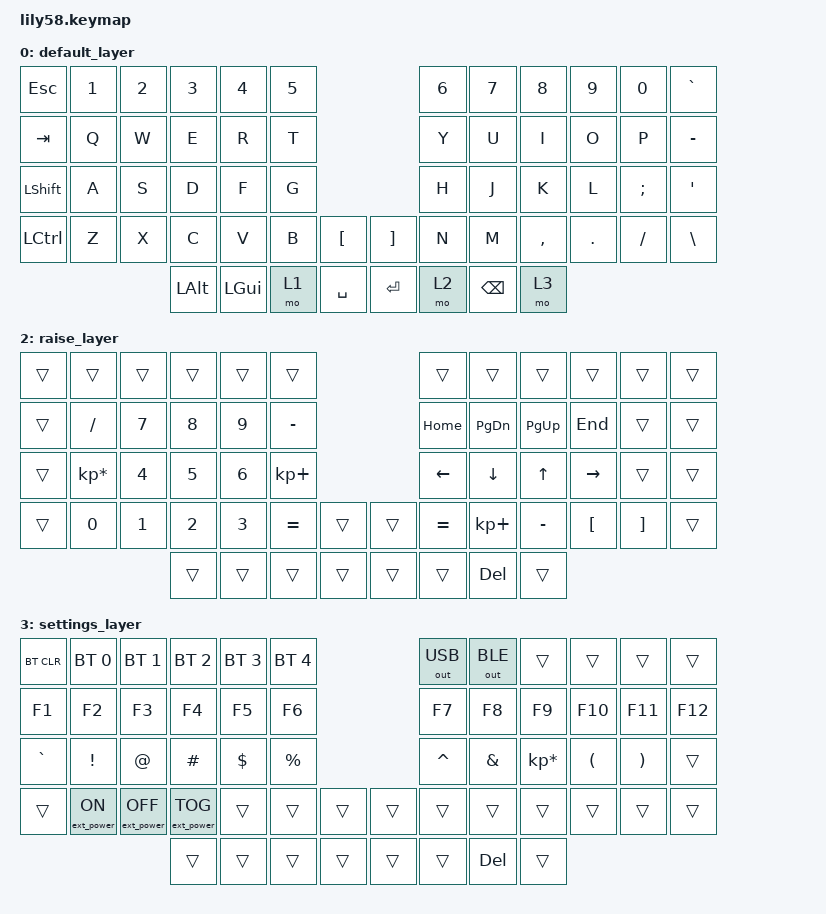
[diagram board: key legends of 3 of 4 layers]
/*
 * Copyright (c) 2020 The ZMK Contributors
 *
 * SPDX-License-Identifier: MIT
 */

#include <behaviors.dtsi>
#include <dt-bindings/zmk/keys.h>
#include <dt-bindings/zmk/bt.h>
#include <dt-bindings/zmk/ext_power.h>
#include <dt-bindings/zmk/outputs.h>

/ {
	keymap {
		compatible = "zmk,keymap";

		default_layer {
// ------------------------------------------------------------------------------------------------------------
// |  ESC  |  1  |  2  |  3   |  4   |  5   |                   |  6   |  7    |  8    |  9   |   0   |   `   |
// |  TAB  |  Q  |  W  |  E   |  R   |  T   |                   |  Y   |  U    |  I    |  O   |   P   |   -   |
// | SHIFT |  A  |  S  |  D   |  F   |  G   |                   |  H   |  J    |  K    |  L   |   ;   |   '   |
// | CTRL  |  Z  |  X  |  C   |  V   |  B   |   "["  |  |  "]"  |  N   |  M    |  ,    |  .   |   /   |   \   |
//                     | ALT  | GUI  | LOWER|  SPACE |  | ENTER | RAISE| BSPC  |SETTINGS|
			bindings = <
&kp ESC   &kp N1 &kp N2 &kp N3   &kp N4   &kp N5                     &kp N6 &kp N7   &kp N8    &kp N9  &kp N0   &kp GRAVE
&kp TAB   &kp Q  &kp W  &kp E    &kp R    &kp T                      &kp Y  &kp U    &kp I     &kp O   &kp P    &kp MINUS
&kp LSHFT &kp A  &kp S  &kp D    &kp F    &kp G                      &kp H  &kp J    &kp K     &kp L   &kp SEMI &kp SQT
&kp LCTRL &kp Z  &kp X  &kp C    &kp V    &kp B  &kp LBKT   &kp RBKT &kp N  &kp M    &kp COMMA &kp DOT &kp FSLH &kp BACKSLASH
                        &kp LALT &kp LGUI &mo 1  &kp SPACE  &kp RET  &mo 2  &kp BSPC &mo 3
			>;

			sensor-bindings = <&inc_dec_kp C_VOL_UP C_VOL_DN>;
		};

		lower_layer {
// ------------------------------------------------------------------------------------------------------------
// |       |  F1 |  F2 |  F3  |  F4  |  F5  |                   |  F6  |  F7   |  F8   |  F9  |  F10  |  F11  |
// |   `   |  !  |  @  |  #   |  $   |  %   |                   |  ^   |  &    |  *    |  (   |   )   |  F12  |
// | SHIFT |  1  |  2  |  3   |  4   |  5   |                   |  6   |   7   |   8   |  9   |   0   |       |
// |       |     |     |      |      |      |        |  |       |  =   |  +    |  -    |  {   |   }   |       |
//                     |      |      |      |        |  |       |      |  DEL  |       |
			bindings = <
&trans 		&kp F1      &kp F2	&kp F3		&kp F4		&kp F5                 	&kp F6		&kp F7    	&kp F8    		&kp F9		&kp F10   &kp F11
&kp GRAVE   &kp EXCL    &kp AT	&kp HASH	&kp DOLLAR	&kp PRCNT              	&kp CARET	&kp AMPS  	&kp KP_MULTIPLY	&kp LPAR 	&kp RPAR  &kp F12
&kp LSHFT 	&kp N1 	    &kp N2 	&kp N3  	&kp N4  	&kp N5                 	&kp N6     	&kp N7    	&kp N8    		&kp N9   	&kp N0    &trans
&trans     	&trans	    &trans 	&trans 		&trans      &trans   				&kp EQUAL   &kp KP_PLUS &kp MINUS		&kp LBRC  &kp RBRC    &trans
                                              &trans            &trans       &trans    &trans   &trans    &mo 3    &kp DEL    &trans
			>;

			sensor-bindings = <&inc_dec_kp C_VOL_UP C_VOL_DN>;
		};

		raise_layer {
// ------------------------------------------------------------------------------------------------------------
// |       |     |     |      |      |      |                   |      |       |       |      |       |       |
// |       |  /  |  7  |  8   |  9   |  -   |                   | HOME | PGDN  | PGUP  | END  |       |       |
// |       |  *  |  4  |  5   |  6   |  +   |                   |  <-  |   v   |   ^   |  ->  |       |       |
// |       |  0  |  1  |  2   |  3   |  =   |        |  |       |  =   |   +   |   -   |  [   |   ]   |       |
//                     |      |  .   |      |        |  |       |      |  DEL  |       |
			bindings = <
&trans    &trans &trans &trans  &trans  &trans                       &trans      &trans    &trans    &trans    &trans    &trans
&trans    &kp FSLH &kp N7 &kp N8  &kp N9  &kp MINUS                       &kp HOME      &kp PG_DN    &kp PG_UP    &kp END    &trans    &trans
&trans    &kp KP_MULTIPLY &kp N4 &kp N5  &kp N6  &kp KP_PLUS                       &kp LEFT    &kp DOWN  &kp UP    &kp RIGHT &trans &trans
&trans    &kp N0 &kp N1 &kp N2 &kp N3 &kp EQUAL   &trans   &trans    &kp EQUAL &kp KP_PLUS &kp MINUS &kp LBKT  &kp RBKT  &trans
                        &trans  &trans  &trans    &trans   &trans    &trans      &kp DEL    &trans
			>;

			sensor-bindings = <&inc_dec_kp C_VOL_UP C_VOL_DN>;
		};

		settings_layer {
// ------------------------------------------------------------------------------------------------------------
// | BTCLR | BT1 | BT2  |  BT3 |  BT4 |  BT5 |                   |OUTUSB|OUTBLE |       |      |       |       |
// |  F1   |  F2 |  F3  |  F4  |  F5  |  F6  |                   |  F7  |  F8   |  F9   |  F10 |  F11  |  F12  |
// |   `   |  !  |  @   |  #   |  $   |  %   |                   |  ^   |  &    |  *    |  (   |   )   |       |
// |       |EP_ON|EP_OFF|EP_TOG|      |      |        |  |       |      |       |       |      |       |       |
//                      |      |      |      |        |  |       |      |  DEL  |       |
			bindings = <
&bt BT_CLR &bt BT_SEL 0     &bt BT_SEL 1      &bt BT_SEL 2      &bt BT_SEL 3 &bt BT_SEL 4                 &out OUT_USB    &out OUT_BLE    &trans          &trans    &trans    &trans
&kp F1     &kp F2           &kp F3            &kp F4            &kp F5       &kp F6                       &kp F7    &kp F8    &kp F9          &kp F10   &kp F11   &kp F12
&kp GRAVE  &kp EXCL         &kp AT            &kp HASH          &kp DOLLAR   &kp PRCNT                    &kp CARET &kp AMPS  &kp KP_MULTIPLY &kp LPAR  &kp RPAR  &trans
&trans     &ext_power EP_ON &ext_power EP_OFF &ext_power EP_TOG &trans       &trans    &trans   &trans    &trans    &trans &trans     &trans  &trans  &trans
                                              &trans            &trans       &trans    &trans   &trans    &trans    &kp DEL    &trans
			>;

			sensor-bindings = <&inc_dec_kp C_VOL_UP C_VOL_DN>;
		};

// 		arrow_layer {
// // ------------------------------------------------------------------------------------------------------------
// // |       |     |     |      |      |      |                   |      |       |       |      |       |       |
// // |       |     |     |      |      |      |                   |      |       |   ^   |      |       |       |
// // |       |     |     |      |      |      |                   |      |   <   |   v   |   >  |       |       |
// // |       |     |     |      |      |      |        |  |       |      |       |       |      |       |       |
// //                     |      |      |      |        |  |       |      |       |       |
// 			bindings = <
// &trans    &trans &trans &trans  &trans  &trans                       &trans      &trans    &trans    &trans    &trans    &trans
// &trans    &trans &trans &trans  &trans  &trans                       &trans      &trans    &kp UP    &trans    &trans    &trans
// &trans    &trans &trans &trans  &trans  &trans                       &trans      &kp LEFT  &kp DOWN  &kp RIGHT &trans    &trans
// &trans    &trans &trans &trans  &trans  &trans     &trans &trans     &trans      &trans    &trans    &trans    &trans    &trans
//                         &trans  &trans  &trans     &trans &trans     &trans      &trans    &trans
// 			>;

// 			sensor-bindings = <&inc_dec_kp C_VOL_UP C_VOL_DN>;
// 		};
	};
};
